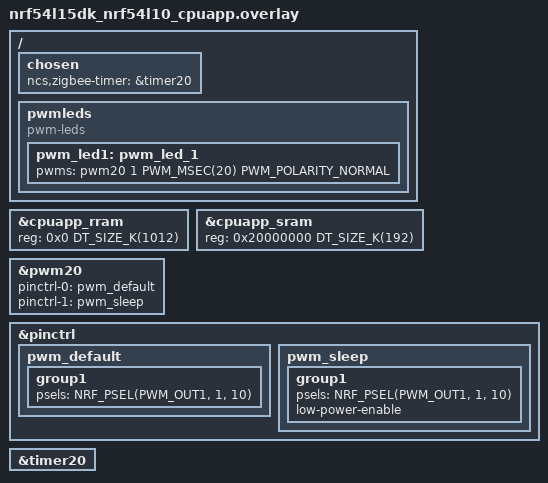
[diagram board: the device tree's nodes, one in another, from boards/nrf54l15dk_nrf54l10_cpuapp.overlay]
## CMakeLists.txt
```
#
# Copyright (c) 2024 Nordic Semiconductor ASA
#
# SPDX-License-Identifier: LicenseRef-Nordic-5-Clause
#

cmake_minimum_required(VERSION 3.20.0)

find_package(Zephyr REQUIRED HINTS $ENV{ZEPHYR_BASE})

project("Zigbee Light Bulb")

target_sources(app PRIVATE
	src/main.cpp
	src/app_task_zigbee.cpp
	src/zboss_mem_globals.c
)

target_include_directories(app PRIVATE include)

# LTO link: zb_memconfig.o from prebuilts is plain ELF (weak gc_*); strong gc_*
# in zb_mem_config_context.h must not be LTO bytecode or ld warns about symbol size.
if(CONFIG_LTO)
	set_source_files_properties(
		src/zboss_mem_globals.c
		PROPERTIES COMPILE_OPTIONS -fno-lto
	)
endif()
```

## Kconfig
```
#
# Copyright (c) 2026 Nordic Semiconductor ASA
#
# SPDX-License-Identifier: LicenseRef-Nordic-5-Clause
#

if ZIGBEE_BT_DFU

config BT_DEVICE_NAME
	default "Zigbee_Bulb"

endif # ZIGBEE_BT_DFU

config MPSL_THREAD_COOP_PRIO
	default 8

source "Kconfig.zephyr"
```

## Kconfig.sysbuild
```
#
# Copyright (c) 2024 Nordic Semiconductor
#
# SPDX-License-Identifier: LicenseRef-Nordic-5-Clause
#

config NRF_DEFAULT_IPC_RADIO
	default y

# Enable IEEE802.15.4 serialization to network core for Zigbee
config NETCORE_IPC_RADIO_IEEE802154
	default y if SOC_SERIES_NRF53

if BOOTLOADER_MCUBOOT

#### DFU multi-image support
config DFU_MULTI_IMAGE_PACKAGE_BUILD
	default y

config DFU_MULTI_IMAGE_PACKAGE_APP
	default y

#### DFU dual core configuration
if SOC_SERIES_NRF53

config PM_EXTERNAL_FLASH_MCUBOOT_SECONDARY
	default y

config MCUBOOT_UPDATEABLE_IMAGES
	default 2

choice MCUBOOT_MODE
	default MCUBOOT_MODE_OVERWRITE_ONLY
endchoice

config SECURE_BOOT_NETCORE
	default y

config NETCORE_APP_UPDATE
	default y

config DFU_MULTI_IMAGE_PACKAGE_NET
	default y

config MCUBOOT_NRF53_MULTI_IMAGE_UPDATE
	default y if NETCORE_APP_UPDATE

endif # SOC_SERIES_NRF53

endif # BOOTLOADER_MCUBOOT

source "${ZEPHYR_BASE}/share/sysbuild/Kconfig"
```

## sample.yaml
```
sample:
  description: Zigbee Light control - light bulb sample
  name: Zigbee Light control
common:
  tags:
    - ci_build
    - smoke
    - sysbuild
    - ci_samples_zigbee
tests:
  sample.zigbee.light_bulb:
    sysbuild: true
    build_only: true
    integration_platforms:
      - nrf52840dk/nrf52840
      - nrf5340dk/nrf5340/cpuapp
      - nrf54l15dk/nrf54l15/cpuapp
      - nrf54lc10dk/nrf54lc10a/cpuapp
      - nrf54lm20dk/nrf54lm20b/cpuapp
      - nrf54lm20dongle/nrf54lm20b/cpuapp
    platform_allow:
      - nrf52840dk/nrf52840
      - nrf5340dk/nrf5340/cpuapp
      - nrf54l15dk/nrf54l10/cpuapp
      - nrf54l15dk/nrf54l15/cpuapp
      - nrf54lc10dk/nrf54lc10a/cpuapp
      - nrf54lm20dk/nrf54lm20a/cpuapp
      - nrf54lm20dk/nrf54lm20b/cpuapp
      - nrf54lm20dongle/nrf54lm20b/cpuapp
  sample.zigbee.light_bulb.fota:
    sysbuild: true
    build_only: true
    extra_args:
      - FILE_SUFFIX=fota
      - SNIPPET=zigbee_fota
    integration_platforms:
      - nrf52840dk/nrf52840
      - nrf5340dk/nrf5340/cpuapp
      - nrf54l15dk/nrf54l15/cpuapp
      - nrf54lm20dk/nrf54lm20b/cpuapp
    platform_allow:
      - nrf52840dk/nrf52840
      - nrf5340dk/nrf5340/cpuapp
      - nrf54l15dk/nrf54l10/cpuapp
      - nrf54l15dk/nrf54l15/cpuapp
      - nrf54lm20dk/nrf54lm20a/cpuapp
      - nrf54lm20dk/nrf54lm20b/cpuapp
  sample.zigbee.light_bulb.fota_and_bt_dfu:
    sysbuild: true
    build_only: true
    extra_args:
      - FILE_SUFFIX=fota
      - SNIPPET=zigbee_fota
      - CONFIG_ZIGBEE_BT_DFU=y
    integration_platforms:
      - nrf54lm20dk/nrf54lm20b/cpuapp
    platform_allow:
      - nrf54lm20dk/nrf54lm20a/cpuapp
      - nrf54lm20dk/nrf54lm20b/cpuapp
  sample.zigbee.light_bulb.io_shell:
    sysbuild: true
    build_only: true
    extra_args: light_bulb_SNIPPET=io_shell
    integration_platforms:
      - nrf54lm20dongle/nrf54lm20b/cpuapp
    platform_allow:
      - nrf54lm20dongle/nrf54lm20b/cpuapp
  sample.zigbee.light_bulb.with_shell:
    sysbuild: true
    build_only: true
    extra_args:
      - CONFIG_ZIGBEE_SHELL=y
      - CONFIG_ZIGBEE_SHELL_DEBUG_CMD=y
      - CONFIG_ZIGBEE_LOGGER_EP=n
      - CONFIG_ZIGBEE_SHELL_ENDPOINT=10
      - CONFIG_LOG_MODE_DEFERRED=y
      - CONFIG_ZIGBEE_TOUCHLINK_TARGET=y
    platform_allow:
      - nrf52840dk/nrf52840
      - nrf5340dk/nrf5340/cpuapp
      - nrf54l15dk/nrf54l10/cpuapp
      - nrf54l15dk/nrf54l15/cpuapp
      - nrf54lc10dk/nrf54lc10a/cpuapp
      - nrf54lm20dk/nrf54lm20a/cpuapp
      - nrf54lm20dk/nrf54lm20b/cpuapp
    tags:
      - no_integration
      - shell
```

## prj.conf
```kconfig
#
# Copyright (c) 2024 Nordic Semiconductor ASA
#
# SPDX-License-Identifier: LicenseRef-Nordic-5-Clause
#

CONFIG_NCS_SAMPLES_DEFAULTS=y

CONFIG_UART_INTERRUPT_DRIVEN=y
CONFIG_SERIAL=y
CONFIG_GPIO=y
CONFIG_PWM=y

# Make sure printk is not printing to the UART console
CONFIG_CONSOLE=y
CONFIG_UART_CONSOLE=y

CONFIG_HEAP_MEM_POOL_SIZE=2048
CONFIG_MAIN_THREAD_PRIORITY=7

CONFIG_ZIGBEE_ADD_ON=y
CONFIG_ZIGBEE_APP_UTILS=y
CONFIG_ZIGBEE_ROLE_ROUTER=y

# Enable DK LED and Buttons library
CONFIG_DK_LIBRARY=y
# Scene extension
CONFIG_ZIGBEE_SCENES=y
```

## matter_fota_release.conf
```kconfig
#
# Copyright (c) 2026 Nordic Semiconductor ASA
#
# SPDX-License-Identifier: LicenseRef-Nordic-5-Clause
#
# Release/size-optimization configuration for combined Zigbee + Matter + Thread (PoC)
# Disables logging, console, and other debug features to reduce flash usage

#######################
# Release Optimizations
#######################

# Disable all debug features
CONFIG_USE_SEGGER_RTT=n
CONFIG_SHELL=n
CONFIG_OPENTHREAD_SHELL=n
CONFIG_CONSOLE=n
CONFIG_UART_CONSOLE=n
CONFIG_SERIAL=n
CONFIG_UART_INTERRUPT_DRIVEN=n
CONFIG_LOG=n
CONFIG_LOG_MODE_MINIMAL=n
CONFIG_ASSERT_VERBOSE=n
CONFIG_ASSERT_NO_FILE_INFO=y
CONFIG_PRINTK=n
CONFIG_PRINTK_SYNC=n
CONFIG_BOOT_BANNER=n

# TODO: Enable LTO to decrease the flash usage after testing
# CONFIG_LTO=y
# CONFIG_ISR_TABLES_LOCAL_DECLARATION=y

# Additional size optimizations
CONFIG_SIZE_OPTIMIZATIONS=y
CONFIG_COMPILER_OPT="-Os"
```

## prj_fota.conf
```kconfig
#
# Copyright (c) 2026 Nordic Semiconductor ASA
#
# SPDX-License-Identifier: LicenseRef-Nordic-5-Clause
#

CONFIG_NCS_SAMPLES_DEFAULTS=y

CONFIG_UART_INTERRUPT_DRIVEN=y
CONFIG_SERIAL=y
CONFIG_GPIO=y
CONFIG_PWM=y

CONFIG_CONSOLE=y
CONFIG_UART_CONSOLE=y

CONFIG_HEAP_MEM_POOL_SIZE=2048
CONFIG_MAIN_THREAD_PRIORITY=7

CONFIG_ZIGBEE_ADD_ON=y
CONFIG_ZIGBEE_APP_UTILS=y
CONFIG_ZIGBEE_ROLE_ROUTER=y

CONFIG_DK_LIBRARY=y
CONFIG_ZIGBEE_SCENES=y

#######################
# Zigbee FOTA overlay #
#######################

CONFIG_ZIGBEE_FOTA=y
CONFIG_ZIGBEE_FOTA_HW_VERSION=52
CONFIG_ZIGBEE_FOTA_ENDPOINT=11
CONFIG_MCUBOOT_IMGTOOL_SIGN_VERSION="1.2.3"
CONFIG_ZIGBEE_FOTA_COMMENT="light_bulb"
CONFIG_ZIGBEE_FOTA_DOWNLOAD_RESUME=y

CONFIG_IMG_MANAGER=y
CONFIG_STREAM_FLASH=y
CONFIG_DFU_TARGET_MCUBOOT=y
CONFIG_IMG_ERASE_PROGRESSIVELY=y
CONFIG_ZIGBEE_FOTA_PROGRESS_EVT=y

CONFIG_NRF_802154_RX_BUFFERS=32
```

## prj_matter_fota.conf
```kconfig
#
# Copyright (c) 2026 Nordic Semiconductor ASA
#
# SPDX-License-Identifier: LicenseRef-Nordic-5-Clause
#
# Debug configuration for combined Zigbee + Matter + Thread (PoC)
# Includes logging, console, and debug features

# Base sample configs
CONFIG_NCS_SAMPLES_DEFAULTS=y

CONFIG_UART_INTERRUPT_DRIVEN=y
CONFIG_SERIAL=y
CONFIG_GPIO=y
CONFIG_PWM=y

# Console
CONFIG_CONSOLE=y
CONFIG_UART_CONSOLE=y

# CONFIG_HEAP_MEM_POOL_SIZE=4096
CONFIG_MAIN_THREAD_PRIORITY=7

#######################
# Zigbee Configuration
#######################

CONFIG_ZIGBEE_ADD_ON=y
CONFIG_ZIGBEE_APP_UTILS=y
# Show Zigbee init/recovery logs (Device first start, network steering recovery).
CONFIG_ZIGBEE_APP_UTILS_LOG_LEVEL_INF=y
CONFIG_ZIGBEE_ROLE_ROUTER=y

# Touchlink target role for the combined Matter build
# CONFIG_ZIGBEE_TOUCHLINK_TARGET=y

# Scene extension
CONFIG_ZIGBEE_SCENES=y

# Enable DK LED and Buttons library
CONFIG_DK_LIBRARY=y

# This example requires more workqueue stack
CONFIG_SYSTEM_WORKQUEUE_STACK_SIZE=2048

CONFIG_ZBOSS_OSIF_LOG_LEVEL_INF=y
CONFIG_ZIGBEE_MATTER_COEXISTENCE_LOG_LEVEL_INF=y

#######################
# Zigbee FOTA Configuration
#######################

# FIXME: Disabled Zigbee FOTA for initial development
# # Enable Zigbee FOTA library
# CONFIG_ZIGBEE_FOTA=y
# CONFIG_ZIGBEE_FOTA_HW_VERSION=52
# CONFIG_ZIGBEE_FOTA_ENDPOINT=5
# CONFIG_MCUBOOT_IMGTOOL_SIGN_VERSION="1.0.0"
# CONFIG_ZIGBEE_FOTA_COMMENT="light_bulb_matter"

# # Ensure an MCUboot-compatible binary is generated.
# CONFIG_IMG_MANAGER=y
# CONFIG_STREAM_FLASH=y
# CONFIG_DFU_TARGET_MCUBOOT=y
# CONFIG_IMG_ERASE_PROGRESSIVELY=y
# CONFIG_ZIGBEE_FOTA_PROGRESS_EVT=y

# # Increase the number of RX buffers for FOTA
# CONFIG_NRF_802154_RX_BUFFERS=32

#######################
# Matter Configuration
#######################

# Enable CHIP (Matter)
CONFIG_CHIP=y
CONFIG_CHIP_PROJECT_CONFIG="include/chip_project_config.h"
CONFIG_CHIP_DEVICE_PRODUCT_NAME="Matter Zigbee Light Bulb"

# Configure ZAP file
CONFIG_NCS_SAMPLE_MATTER_ZAP_FILE_PATH="${APPLICATION_CONFIG_DIR}/src/matter_zap/light_bulb.zap"

# 32773 == 0x8005 (example lighting-app)
CONFIG_CHIP_DEVICE_PRODUCT_ID=32773
CONFIG_STD_CPP17=y

# Enable Matter pairing automatically on application start.
CONFIG_CHIP_ENABLE_PAIRING_AUTOSTART=y

# Enable Matter extended announcement and increase duration to 1 hour.
CONFIG_CHIP_BLE_EXT_ADVERTISING=y
CONFIG_CHIP_BLE_ADVERTISING_DURATION=60

CONFIG_BT_DEVICE_NAME="MatterZigbeeLb"

# Other settings
CONFIG_THREAD_NAME=y
CONFIG_MPU_STACK_GUARD=y
CONFIG_RESET_ON_FATAL_ERROR=n

# Reduce application size
CONFIG_USE_SEGGER_RTT=n

# Increase system workqueue stack for combined protocols (with Thread)
CONFIG_SYSTEM_WORKQUEUE_STACK_SIZE=6144

# Must be a preemptible priority (0–15), not cooperative (-1). With -1, ZBOSS is
# coop priority -1 and is outranked by MPSL Work (prio -8), so it never runs.
# State 128 = _THREAD_QUEUED (runnable); ZBOSS stays queued and never gets CPU.
CONFIG_ZBOSS_DEFAULT_THREAD_PRIORITY=1
CONFIG_ZBOSS_DEFAULT_THREAD_STACK_SIZE=6144

# Libc malloc arena required for Zigbee + Matter coexistence.
# - 0: no libc heap -> Matter init fails (malloc/calloc used during init).
# - -1: "all remaining RAM" -> on this build the computed heap extends past
#   valid RAM and triggers a precise data bus fault in sys_heap_init().
# - Positive value: static BSS heap of that size -> valid heap, no fault.
# Matter uses CHIP_MALLOC_SYS_HEAP for its own allocations; this arena
# covers libc malloc() used elsewhere (init, Zephyr, Zigbee, etc.).
CONFIG_COMMON_LIBC_MALLOC_ARENA_SIZE=-1

## PoC Configuration ##
# Keep Matter shell disabled to avoid getopt conflicts
CONFIG_CHIP_LIB_SHELL=n
CONFIG_NCS_SAMPLE_MATTER_TEST_SHELL=n

# Radio dispatcher 
CONFIG_NRF_802154_CALLBACKS_DISPATCHER=y

# We need it to disable ZBOSS thread
CONFIG_ZIGBEE_DEBUG_FUNCTIONS=y

CONFIG_CHIP_FACTORY_DATA_BUILD=y

# DFU over Bluetooth LE SMP
CONFIG_CHIP_DFU_OVER_BT_SMP=y
```

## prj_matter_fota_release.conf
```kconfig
#
# Copyright (c) 2026 Nordic Semiconductor ASA
#
# SPDX-License-Identifier: LicenseRef-Nordic-5-Clause
#
# Release configuration for combined Zigbee + Matter + Thread (PoC)
# Optimized for minimum memory footprint

# Base sample configs
CONFIG_NCS_SAMPLES_DEFAULTS=y

CONFIG_GPIO=y
CONFIG_PWM=y

CONFIG_HEAP_MEM_POOL_SIZE=4096
CONFIG_MAIN_THREAD_PRIORITY=7

#######################
# Zigbee Configuration
#######################

CONFIG_ZIGBEE_ADD_ON=y
CONFIG_ZIGBEE_APP_UTILS=y
CONFIG_ZIGBEE_ROLE_ROUTER=y

# Scene extension
CONFIG_ZIGBEE_SCENES=y

# Enable DK LED and Buttons library
CONFIG_DK_LIBRARY=y

# This example requires more workqueue stack
CONFIG_SYSTEM_WORKQUEUE_STACK_SIZE=2048

# Networking
CONFIG_NETWORKING=y
CONFIG_NET_IPV6=y
CONFIG_NET_IP_ADDR_CHECK=y
CONFIG_NET_UDP=y
CONFIG_NET_TCP=y
CONFIG_NET_SOCKETS=y

# OpenThread/Thread support for Matter (PoC - not functional with Zigbee)
CONFIG_NET_L2_OPENTHREAD=y
CONFIG_OPENTHREAD_NORDIC_LIBRARY_FTD=y
CONFIG_OPENTHREAD_SLAAC=y
CONFIG_OPENTHREAD_MANUAL_START=y

#######################
# Zigbee FOTA Configuration
#######################

# Enable Zigbee FOTA library
CONFIG_ZIGBEE_FOTA=y
CONFIG_ZIGBEE_FOTA_HW_VERSION=52
CONFIG_ZIGBEE_FOTA_ENDPOINT=5
CONFIG_MCUBOOT_IMGTOOL_SIGN_VERSION="1.0.0"
CONFIG_ZIGBEE_FOTA_COMMENT="light_bulb_matter"

# Ensure an MCUboot-compatible binary is generated.
CONFIG_IMG_MANAGER=y
CONFIG_STREAM_FLASH=y
CONFIG_DFU_TARGET_MCUBOOT=y
CONFIG_IMG_ERASE_PROGRESSIVELY=y
CONFIG_ZIGBEE_FOTA_PROGRESS_EVT=y

# Increase the number of RX buffers for FOTA
CONFIG_NRF_802154_RX_BUFFERS=32

#######################
# Matter Configuration
#######################

# Enable CHIP (Matter)
CONFIG_CHIP=y
CONFIG_CHIP_PROJECT_CONFIG="src/chip_project_config.h"

# Configure ZAP file
CONFIG_NCS_SAMPLE_MATTER_ZAP_FILE_PATH="${APPLICATION_CONFIG_DIR}/src/matter_zap/light_bulb.zap"

# 32773 == 0x8005 (example lighting-app)
CONFIG_CHIP_DEVICE_PRODUCT_ID=32773
CONFIG_STD_CPP17=y

# Enable Matter pairing automatically on application start.
CONFIG_CHIP_ENABLE_PAIRING_AUTOSTART=y

# Enable Matter extended announcement and increase duration to 1 hour.
CONFIG_CHIP_BLE_EXT_ADVERTISING=y
CONFIG_CHIP_BLE_ADVERTISING_DURATION=60

# Bluetooth Low Energy configuration
CONFIG_BT=y
CONFIG_BT_PERIPHERAL=y
CONFIG_BT_DEVICE_NAME="MatterZigbeeLight"
CONFIG_BT_DEVICE_APPEARANCE=0
CONFIG_BT_MAX_CONN=1
CONFIG_BT_L2CAP_TX_MTU=247
CONFIG_BT_BUF_ACL_RX_SIZE=251
CONFIG_BT_BUF_ACL_TX_SIZE=251
CONFIG_BT_RX_STACK_SIZE=1200

# Other settings
CONFIG_THREAD_NAME=n
CONFIG_MPU_STACK_GUARD=y
CONFIG_RESET_ON_FATAL_ERROR=y

# Enable Factory Data feature
CONFIG_CHIP_FACTORY_DATA=y
CONFIG_CHIP_FACTORY_DATA_BUILD=y

# Matter commissioning
CONFIG_CHIP_COMMISSIONABLE_DEVICE_TYPE=y
CONFIG_CHIP_DEVICE_TYPE=256

# Enable Matter OTA (aligned with Zigbee FOTA)
CONFIG_CHIP_OTA_REQUESTOR=y

# Increase system workqueue stack for combined protocols (with Thread)
CONFIG_SYSTEM_WORKQUEUE_STACK_SIZE=4096

# Memory settings for Zigbee + Matter + Thread (PoC)
CONFIG_MAIN_STACK_SIZE=4096
CONFIG_CHIP_MALLOC_SYS_HEAP=y
CONFIG_CHIP_MALLOC_SYS_HEAP_SIZE=32768

# Thread stack sizes
CONFIG_NET_TX_STACK_SIZE=1200
CONFIG_NET_RX_STACK_SIZE=1500

# Crypto - PSA Crypto Backend
CONFIG_NORDIC_SECURITY_BACKEND=y
CONFIG_CHIP_CRYPTO_PSA=y

# Enable legacy mbedTLS crypto for Matter SPAKE2+ (requires mbedtls_ecp_muladd)
CONFIG_MBEDTLS_LEGACY_CRYPTO_C=y
CONFIG_MBEDTLS_ECP_C=y

# Storage - use ZMS for nRF54L (NVS not supported)
CONFIG_ZMS=y
CONFIG_SETTINGS=y
CONFIG_SETTINGS_ZMS=y
CONFIG_FLASH=y
CONFIG_FLASH_MAP=y
CONFIG_MPU_ALLOW_FLASH_WRITE=y

# Trusted storage backend for Matter PSA crypto keys
CONFIG_TRUSTED_STORAGE=y
CONFIG_TRUSTED_STORAGE_BACKEND_AEAD=y
CONFIG_TRUSTED_STORAGE_STORAGE_BACKEND_SETTINGS=y

# Additional platform requirements for Matter
CONFIG_HWINFO=y
CONFIG_REBOOT=y
CONFIG_ENTROPY_GENERATOR=y

# Matter thread requirements
CONFIG_SCHED_CPU_MASK=y

# Watchdog
CONFIG_TASK_WDT=y

# Matter common infrastructure configs (needed even without Thread)

# Enable BT GATT for Matter BLE commissioning
CONFIG_BT_GATT_DYNAMIC_DB=y
CONFIG_BT_GATT_SERVICE_CHANGED=y
CONFIG_BT_GATT_CACHING=y
CONFIG_BT_GATT_ENFORCE_SUBSCRIPTION=n


## PoC Configuration ##
# Note: This configuration links all three stacks (Zigbee, Thread, Matter) for memory estimation
# It will have runtime conflicts as Zigbee and Thread cannot share 802.15.4 radio simultaneously
# This is intentional - goal is to measure maximum memory footprint

# Keep Matter shell disabled to avoid getopt conflicts
CONFIG_CHIP_LIB_SHELL=n
CONFIG_NCS_SAMPLE_MATTER_TEST_SHELL=n

#######################
# Release Optimizations
#######################

# Disable all debug features
CONFIG_USE_SEGGER_RTT=n
CONFIG_SHELL=n
CONFIG_OPENTHREAD_SHELL=n
CONFIG_CONSOLE=n
CONFIG_UART_CONSOLE=n
CONFIG_SERIAL=n
CONFIG_UART_INTERRUPT_DRIVEN=n
CONFIG_LOG=n
CONFIG_LOG_MODE_MINIMAL=n
CONFIG_ASSERT_VERBOSE=n
CONFIG_ASSERT_NO_FILE_INFO=y
CONFIG_PRINTK=n
CONFIG_PRINTK_SYNC=n
CONFIG_BOOT_BANNER=n

# Enable LTO to decrease the flash usage
CONFIG_LTO=y
CONFIG_ISR_TABLES_LOCAL_DECLARATION=y

# Additional size optimizations
CONFIG_SIZE_OPTIMIZATIONS=y
CONFIG_COMPILER_OPT="-Os"
```

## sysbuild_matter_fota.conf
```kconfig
#
# Copyright (c) 2026 Nordic Semiconductor ASA
#
# SPDX-License-Identifier: LicenseRef-Nordic-5-Clause
#

# Enable Matter support in sysbuild
SB_CONFIG_MATTER=y
SB_CONFIG_MATTER_FACTORY_DATA_GENERATE=y

# Disable partition manager
SB_CONFIG_PARTITION_MANAGER=n

# MCUBoot configuration
SB_CONFIG_MCUBOOT_MODE_OVERWRITE_ONLY=y
SB_CONFIG_MCUBOOT_COMPRESSED_IMAGE_SUPPORT=y
```

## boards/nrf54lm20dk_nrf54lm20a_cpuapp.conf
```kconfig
#
# Copyright (c) 2026 Nordic Semiconductor ASA
#
# SPDX-License-Identifier: LicenseRef-Nordic-5-Clause
#


# Fixme, the new ECC handling is broken, and let's disable the new feature for now for testing.
# If cracen is fixed, we can enable this again.
CONFIG_CRACEN_ECC_COUNTERMEASURES=n
```

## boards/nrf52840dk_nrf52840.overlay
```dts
/*
 * Copyright (c) 2025 Nordic Semiconductor ASA
 *
 * SPDX-License-Identifier: LicenseRef-Nordic-5-Clause
 */

#include <nrf52840_partitions.dtsi>

/ {
	pwmleds {
		pwm_led1: pwm_led_1 {
			pwms = <&pwm0 1 PWM_MSEC(20) PWM_POLARITY_INVERTED>;
		};
	};

	chosen {
		ncs,zigbee-timer = &timer2;
	};
};

&pwm0 {
	pinctrl-0 = <&pwm0_default_alt>;
	pinctrl-1 = <&pwm0_sleep_alt>;
	pinctrl-names = "default", "sleep";
};

&pinctrl {
	pwm0_default_alt: pwm0_default_alt {
		group1 {
			psels = <NRF_PSEL(PWM_OUT1, 0, 14)>;
			nordic,invert;
		};
	};

	pwm0_sleep_alt: pwm0_sleep_alt {
		group1 {
			psels = <NRF_PSEL(PWM_OUT1, 0, 14)>;
			low-power-enable;
		};
	};
};

&timer2 {
	status = "okay";
};
```

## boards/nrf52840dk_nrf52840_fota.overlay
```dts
/*
 * Copyright (c) 2026 Nordic Semiconductor ASA
 *
 * SPDX-License-Identifier: LicenseRef-Nordic-5-Clause
 */

#include <nrf52840_partitions.dtsi>
#include <ext_flash/nrf52840dk_partitions.dtsi>

/ {
	pwmleds {
		pwm_led1: pwm_led_1 {
			pwms = <&pwm0 1 PWM_MSEC(20) PWM_POLARITY_INVERTED>;
		};
	};

	chosen {
		ncs,zigbee-timer = &timer2;
	};
};

&pwm0 {
	pinctrl-0 = <&pwm0_default_alt>;
	pinctrl-1 = <&pwm0_sleep_alt>;
	pinctrl-names = "default", "sleep";
};

&pinctrl {
	pwm0_default_alt: pwm0_default_alt {
		group1 {
			psels = <NRF_PSEL(PWM_OUT1, 0, 14)>;
			nordic,invert;
		};
	};

	pwm0_sleep_alt: pwm0_sleep_alt {
		group1 {
			psels = <NRF_PSEL(PWM_OUT1, 0, 14)>;
			low-power-enable;
		};
	};
};

&timer2 {
	status = "okay";
};
```

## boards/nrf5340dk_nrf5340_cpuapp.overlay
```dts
/*
 * Copyright (c) 2025 Nordic Semiconductor ASA
 *
 * SPDX-License-Identifier: LicenseRef-Nordic-5-Clause
 */

#include <nrf5340_cpuapp_partitions.dtsi>

/ {
	pwmleds {
		compatible = "pwm-leds";

		pwm_led1: pwm_led_1 {
			pwms = <&pwm0 1 PWM_MSEC(20) PWM_POLARITY_INVERTED>;
		};
	};

	chosen {
		ncs,zigbee-timer = &timer2;
	};
};

&pwm0 {
	pinctrl-0 = <&pwm0_default_alt>;
	pinctrl-1 = <&pwm0_sleep_alt>;
	pinctrl-names = "default", "sleep";
};

&pinctrl {
	pwm0_default_alt: pwm0_default_alt {
		group1 {
			psels = <NRF_PSEL(PWM_OUT1, 0, 29)>;
			nordic,invert;
		};
	};

	pwm0_sleep_alt: pwm0_sleep_alt {
		group1 {
			psels = <NRF_PSEL(PWM_OUT1, 0, 29)>;
			low-power-enable;
		};
	};
};

&timer2 {
	status = "okay";
};
```

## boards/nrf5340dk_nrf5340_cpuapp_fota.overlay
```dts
/*
 * Copyright (c) 2026 Nordic Semiconductor ASA
 *
 * SPDX-License-Identifier: LicenseRef-Nordic-5-Clause
 */

#include <nrf5340_cpuapp_partitions.dtsi>
#include <ext_flash/nrf5340dk_cpuapp_partitions.dtsi>

/ {
	pwmleds {
		compatible = "pwm-leds";

		pwm_led1: pwm_led_1 {
			pwms = <&pwm0 1 PWM_MSEC(20) PWM_POLARITY_INVERTED>;
		};
	};

	chosen {
		ncs,zigbee-timer = &timer2;
	};
};

&pwm0 {
	status = "okay";
	pinctrl-0 = <&pwm0_default_alt>;
	pinctrl-1 = <&pwm0_sleep_alt>;
	pinctrl-names = "default", "sleep";
};

&pinctrl {
	pwm0_default_alt: pwm0_default_alt {
		group1 {
			psels = <NRF_PSEL(PWM_OUT1, 0, 29)>;
			nordic,invert;
		};
	};

	pwm0_sleep_alt: pwm0_sleep_alt {
		group1 {
			psels = <NRF_PSEL(PWM_OUT1, 0, 29)>;
			low-power-enable;
		};
	};
};

&timer2 {
	status = "okay";
};
```

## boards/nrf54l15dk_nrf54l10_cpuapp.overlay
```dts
/*
 * Copyright (c) 2024 Nordic Semiconductor ASA
 *
 * SPDX-License-Identifier: LicenseRef-Nordic-5-Clause
 */

#include <nrf54l10_cpuapp_partitions.dtsi>

/ {
	chosen {
		ncs,zigbee-timer = &timer20;
	};

	pwmleds {
		compatible = "pwm-leds";

		pwm_led1: pwm_led_1 {
			pwms = <&pwm20 1 PWM_MSEC(20) PWM_POLARITY_NORMAL>;
		};
	};
};

// restore full RRAM and SRAM space - by default some parts are dedicated to FLPR
&cpuapp_rram {
	reg = <0x0 DT_SIZE_K(1012)>;
};

&cpuapp_sram {
	reg = <0x20000000 DT_SIZE_K(192)>;
	ranges = <0x0 0x20000000 DT_SIZE_K(192)>;
};

&pwm20 {
	status = "okay";
	pinctrl-0 = <&pwm_default>;
	pinctrl-1 = <&pwm_sleep>;
	pinctrl-names = "default", "sleep";
};

&pinctrl {
	pwm_default: pwm_default {
		group1 {
			psels = <NRF_PSEL(PWM_OUT1, 1, 10)>;
		};
	};

	pwm_sleep: pwm_sleep {
		group1 {
			psels = <NRF_PSEL(PWM_OUT1, 1, 10)>;
			low-power-enable;
		};
	};
};

&timer20 {
	status = "okay";
};
```

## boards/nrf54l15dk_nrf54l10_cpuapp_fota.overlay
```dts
/*
 * Copyright (c) 2026 Nordic Semiconductor ASA
 *
 * SPDX-License-Identifier: LicenseRef-Nordic-5-Clause
 */

#include <nrf54l10_cpuapp_partitions.dtsi>
#include <ext_flash/nrf54l10dk_cpuapp_partitions.dtsi>
```

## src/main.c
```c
/*
 * Copyright (c) 2024 Nordic Semiconductor ASA
 *
 * SPDX-License-Identifier: LicenseRef-Nordic-5-Clause
 */

/** @file
 *
 * @brief Simple Zigbee light bulb implementation.
 */

#include <zephyr/types.h>
#include <zephyr/kernel.h>
#include <zephyr/device.h>
#include <soc.h>
#include <zephyr/drivers/pwm.h>
#include <zephyr/logging/log.h>
#include <dk_buttons_and_leds.h>
#include <zephyr/settings/settings.h>

#include <zboss_api.h>
#include <zboss_api_addons.h>
#include <zb_mem_config_med.h>
#include <zigbee/zigbee_app_utils.h>
#include <zigbee/zigbee_error_handler.h>
#include <zigbee/zigbee_zcl_scenes.h>
#include <zboss_api_zcl.h>
#include <zboss_api_zdo.h>
#include <zb_nrf_platform.h>
#include "zb_dimmable_light.h"

#define RUN_STATUS_LED                  DK_LED1
#define RUN_LED_BLINK_INTERVAL          1000

/* Device endpoint, used to receive light controlling commands. */
#define DIMMABLE_LIGHT_ENDPOINT         10

/* Version of the application software (1 byte). */
#define BULB_INIT_BASIC_APP_VERSION     01

/* Version of the implementation of the Zigbee stack (1 byte). */
#define BULB_INIT_BASIC_STACK_VERSION   10

/* Version of the hardware of the device (1 byte). */
#define BULB_INIT_BASIC_HW_VERSION      11

/* Manufacturer name (32 bytes). */
#define BULB_INIT_BASIC_MANUF_NAME      "Nordic"

/* Model number assigned by manufacturer (32-bytes long string). */
#define BULB_INIT_BASIC_MODEL_ID        "Dimable_Light_v0.1"

/* First 8 bytes specify the date of manufacturer of the device
 * in ISO 8601 format (YYYYMMDD). The rest (8 bytes) are manufacturer specific.
 */
#define BULB_INIT_BASIC_DATE_CODE       "20200329"

/* Type of power sources available for the device.
 * For possible values see section 3.2.2.2.8 of ZCL specification.
 */
#define BULB_INIT_BASIC_POWER_SOURCE    ZB_ZCL_BASIC_POWER_SOURCE_DC_SOURCE

/* Describes the physical location of the device (16 bytes).
 * May be modified during commissioning process.
 */
#define BULB_INIT_BASIC_LOCATION_DESC   "Office desk"

/* Describes the type of physical environment.
 * For possible values see section 3.2.2.2.10 of ZCL specification.
 */
#define BULB_INIT_BASIC_PH_ENV          ZB_ZCL_BASIC_ENV_UNSPECIFIED

/* LED indicating that light switch successfully joind Zigbee network. */
#define ZIGBEE_NETWORK_STATE_LED        DK_LED3

/* LED immitaing dimmable light bulb - define for informational
 * purposes only.
 */
#define BULB_LED                        DK_LED4

/* Button used to enter the Bulb into the Identify mode. */
#define IDENTIFY_MODE_BUTTON            DK_BTN4_MSK

/* Use onboard led4 to act as a light bulb.
 * The app.overlay file has this at node label "pwm_led3" in /pwmleds.
 */
#define PWM_DK_LED_NODE                DT_NODELABEL(pwm_led3)

#if DT_NODE_HAS_STATUS(PWM_DK_LED_NODE, okay)
static const struct pwm_dt_spec led_pwm = PWM_DT_SPEC_GET(PWM_DK_LED_NODE);
#else
#error "Choose supported PWM driver"
#endif

/* Led PWM period, calculated for 100 Hz signal - in microseconds. */
#define LED_PWM_PERIOD_US               (USEC_PER_SEC / 100U)

#ifndef ZB_ROUTER_ROLE
#error Define ZB_ROUTER_ROLE to compile router source code.
#endif

/* Button to start Factory Reset */
#define FACTORY_RESET_BUTTON IDENTIFY_MODE_BUTTON

LOG_MODULE_REGISTER(app, LOG_LEVEL_INF);

/* Main application customizable context.
 * Stores all settings and static values.
 */
typedef struct {
	zb_zcl_basic_attrs_ext_t basic_attr;
	zb_zcl_identify_attrs_t identify_attr;
	zb_zcl_scenes_attrs_t scenes_attr;
	zb_zcl_groups_attrs_t groups_attr;
	zb_zcl_on_off_attrs_t on_off_attr;
	zb_zcl_level_control_attrs_t level_control_attr;
} bulb_device_ctx_t;

/* Zigbee device application context storage. */
static bulb_device_ctx_t dev_ctx;

ZB_ZCL_DECLARE_IDENTIFY_ATTRIB_LIST(
	identify_attr_list,
	&dev_ctx.identify_attr.identify_time);

ZB_ZCL_DECLARE_GROUPS_ATTRIB_LIST(
	groups_attr_list,
	&dev_ctx.groups_attr.name_support);

ZB_ZCL_DECLARE_SCENES_ATTRIB_LIST(
	scenes_attr_list,
	&dev_ctx.scenes_attr.scene_count,
	&dev_ctx.scenes_attr.current_scene,
	&dev_ctx.scenes_attr.current_group,
	&dev_ctx.scenes_attr.scene_valid,
	&dev_ctx.scenes_attr.name_support);

ZB_ZCL_DECLARE_BASIC_ATTRIB_LIST_EXT(
	basic_attr_list,
	&dev_ctx.basic_attr.zcl_version,
	&dev_ctx.basic_attr.app_version,
	&dev_ctx.basic_attr.stack_version,
	&dev_ctx.basic_attr.hw_version,
	dev_ctx.basic_attr.mf_name,
	dev_ctx.basic_attr.model_id,
	dev_ctx.basic_attr.date_code,
	&dev_ctx.basic_attr.power_source,
	dev_ctx.basic_attr.location_id,
	&dev_ctx.basic_attr.ph_env,
	dev_ctx.basic_attr.sw_ver);

/* On/Off cluster attributes additions data */
ZB_ZCL_DECLARE_ON_OFF_ATTRIB_LIST(
	on_off_attr_list,
	&dev_ctx.on_off_attr.on_off);

ZB_ZCL_DECLARE_LEVEL_CONTROL_ATTRIB_LIST(
	level_control_attr_list,
	&dev_ctx.level_control_attr.current_level,
	&dev_ctx.level_control_attr.remaining_time);

ZB_DECLARE_DIMMABLE_LIGHT_CLUSTER_LIST(
	dimmable_light_clusters,
	basic_attr_list,
	identify_attr_list,
	groups_attr_list,
	scenes_attr_list,
	on_off_attr_list,
	level_control_attr_list);


ZB_DECLARE_DIMMABLE_LIGHT_EP(
	dimmable_light_ep,
	DIMMABLE_LIGHT_ENDPOINT,
	dimmable_light_clusters);

ZBOSS_DECLARE_DEVICE_CTX_1_EP(
	dimmable_light_ctx,
	dimmable_light_ep);

/**@brief Starts identifying the device.
 *
 * @param  bufid  Unused parameter, required by ZBOSS scheduler API.
 */
static void start_identifying(zb_bufid_t bufid)
{
	ZVUNUSED(bufid);

	if (ZB_JOINED()) {
		/* Check if endpoint is in identifying mode,
		 * if not, put desired endpoint in identifying mode.
		 */
		if (dev_ctx.identify_attr.identify_time ==
		    ZB_ZCL_IDENTIFY_IDENTIFY_TIME_DEFAULT_VALUE) {

			zb_ret_t zb_err_code = zb_bdb_finding_binding_target(
				DIMMABLE_LIGHT_ENDPOINT);

			if (zb_err_code == RET_OK) {
				LOG_INF("Enter identify mode");
			} else if (zb_err_code == RET_INVALID_STATE) {
				LOG_WRN("RET_INVALID_STATE - Cannot enter identify mode");
			} else {
				ZB_ERROR_CHECK(zb_err_code);
			}
		} else {
			LOG_INF("Cancel identify mode");
			zb_bdb_finding_binding_target_cancel();
		}
	} else {
		LOG_WRN("Device not in a network - cannot enter identify mode");
	}
}

/**@brief Callback for button events.
 *
 * @param[in]   button_state  Bitmask containing the state of the buttons.
 * @param[in]   has_changed   Bitmask containing buttons that have changed their state.
 */
static void button_changed(uint32_t button_state, uint32_t has_changed)
{
	if (IDENTIFY_MODE_BUTTON & has_changed) {
		if (IDENTIFY_MODE_BUTTON & button_state) {
			/* Button changed its state to pressed */
		} else {
			/* Button changed its state to released */
			if (was_factory_reset_done()) {
				/* The long press was for Factory Reset */
				LOG_DBG("After Factory Reset - ignore button release");
			} else   {
				/* Button released before Factory Reset */

				/* Start identification mode */
				ZB_SCHEDULE_APP_CALLBACK(start_identifying, 0);
			}
		}
	}

	check_factory_reset_button(button_state, has_changed);
}

/**@brief Function for initializing additional PWM leds. */
static void pwm_led_init(void)
{
	if (!device_is_ready(led_pwm.dev)) {
		LOG_ERR("Error: PWM device %s is not ready",
			led_pwm.dev->name);
	}
}

/**@brief Function for initializing LEDs and Buttons. */
static void configure_gpio(void)
{
	int err;

	err = dk_buttons_init(button_changed);
	if (err) {
		LOG_ERR("Cannot init buttons (err: %d)", err);
	}

	err = dk_leds_init();
	if (err) {
		LOG_ERR("Cannot init LEDs (err: %d)", err);
	}

	pwm_led_init();
}

/**@brief Sets brightness of bulb luminous executive element
 *
 * @param[in] brightness_level Brightness level, allowed values 0 ... 255,
 *                             0 - turn off, 255 - full brightness.
 */
static void light_bulb_set_brightness(zb_uint8_t brightness_level)
{
	uint32_t pulse = brightness_level * LED_PWM_PERIOD_US / 255U;

	if (pwm_set_dt(&led_pwm, PWM_USEC(LED_PWM_PERIOD_US), PWM_USEC(pulse))) {
		LOG_ERR("Pwm led 4 set fails:\n");
		return;
	}
}

/**@brief Function for setting the light bulb brightness.
 *
 * @param[in] new_level   Light bulb brightness value.
 */
static void level_control_set_value(zb_uint16_t new_level)
{
	LOG_INF("Set level value: %i", new_level);

	ZB_ZCL_SET_ATTRIBUTE(
		DIMMABLE_LIGHT_ENDPOINT,
		ZB_ZCL_CLUSTER_ID_LEVEL_CONTROL,
		ZB_ZCL_CLUSTER_SERVER_ROLE,
		ZB_ZCL_ATTR_LEVEL_CONTROL_CURRENT_LEVEL_ID,
		(zb_uint8_t *)&new_level,
		ZB_FALSE);

	light_bulb_set_brightness(new_level);
}

/**@brief Function for turning ON/OFF the light bulb.
 *
 * @param[in]   on   Boolean light bulb state.
 */
static void on_off_set_value(zb_bool_t on)
{
	LOG_INF("Set ON/OFF value: %i", on);

	ZB_ZCL_SET_ATTRIBUTE(
		DIMMABLE_LIGHT_ENDPOINT,
		ZB_ZCL_CLUSTER_ID_ON_OFF,
		ZB_ZCL_CLUSTER_SERVER_ROLE,
		ZB_ZCL_ATTR_ON_OFF_ON_OFF_ID,
		(zb_uint8_t *)&on,
		ZB_FALSE);

	if (on) {
		light_bulb_set_brightness(dev_ctx.level_control_attr.current_level);
	} else {
		light_bulb_set_brightness(0U);
	}
}

/**@brief Function to toggle the identify LED - BULB_LED is used for this.
 *
 * @param  bufid  Unused parameter, required by ZBOSS scheduler API.
 */
static void toggle_identify_led(zb_bufid_t bufid)
{
	static int blink_status;

	light_bulb_set_brightness(((++blink_status) % 2) ? (255U) : (0U));
	ZB_SCHEDULE_APP_ALARM(toggle_identify_led, bufid, ZB_MILLISECONDS_TO_BEACON_INTERVAL(100));
}

/**@brief Function to handle identify notification events on the first endpoint.
 *
 * @param  bufid  Unused parameter, required by ZBOSS scheduler API.
 */
static void identify_cb(zb_bufid_t bufid)
{
	zb_ret_t zb_err_code;

	if (bufid) {
		/* Schedule a self-scheduling function that will toggle the LED. */
		ZB_SCHEDULE_APP_CALLBACK(toggle_identify_led, bufid);
	} else {
		/* Cancel the toggling function alarm and restore current Zigbee LED state. */
		zb_err_code = ZB_SCHEDULE_APP_ALARM_CANCEL(toggle_identify_led, ZB_ALARM_ANY_PARAM);
		ZVUNUSED(zb_err_code);

		if (dev_ctx.on_off_attr.on_off) {
			light_bulb_set_brightness(dev_ctx.level_control_attr.current_level);
		} else {
			light_bulb_set_brightness(0U);
		}
	}
}

/**@brief Function for initializing all clusters attributes.
 */
static void bulb_clusters_attr_init(void)
{
	/* Basic cluster attributes data */
	dev_ctx.basic_attr.zcl_version = ZB_ZCL_VERSION;
	dev_ctx.basic_attr.app_version = BULB_INIT_BASIC_APP_VERSION;
	dev_ctx.basic_attr.stack_version = BULB_INIT_BASIC_STACK_VERSION;
	dev_ctx.basic_attr.hw_version = BULB_INIT_BASIC_HW_VERSION;

	/* Use ZB_ZCL_SET_STRING_VAL to set strings, because the first byte
	 * should contain string length without trailing zero.
	 *
	 * For example "test" string will be encoded as:
	 *   [(0x4), 't', 'e', 's', 't']
	 */
	ZB_ZCL_SET_STRING_VAL(
		dev_ctx.basic_attr.mf_name,
		BULB_INIT_BASIC_MANUF_NAME,
		ZB_ZCL_STRING_CONST_SIZE(BULB_INIT_BASIC_MANUF_NAME));

	ZB_ZCL_SET_STRING_VAL(
		dev_ctx.basic_attr.model_id,
		BULB_INIT_BASIC_MODEL_ID,
		ZB_ZCL_STRING_CONST_SIZE(BULB_INIT_BASIC_MODEL_ID));

	ZB_ZCL_SET_STRING_VAL(
		dev_ctx.basic_attr.date_code,
		BULB_INIT_BASIC_DATE_CODE,
		ZB_ZCL_STRING_CONST_SIZE(BULB_INIT_BASIC_DATE_CODE));

	dev_ctx.basic_attr.power_source = BULB_INIT_BASIC_POWER_SOURCE;

	ZB_ZCL_SET_STRING_VAL(
		dev_ctx.basic_attr.location_id,
		BULB_INIT_BASIC_LOCATION_DESC,
		ZB_ZCL_STRING_CONST_SIZE(BULB_INIT_BASIC_LOCATION_DESC));

	dev_ctx.basic_attr.ph_env = BULB_INIT_BASIC_PH_ENV;

	/* Identify cluster attributes data. */
	dev_ctx.identify_attr.identify_time =
		ZB_ZCL_IDENTIFY_IDENTIFY_TIME_DEFAULT_VALUE;

	/* On/Off cluster attributes data. */
	dev_ctx.on_off_attr.on_off = (zb_bool_t)ZB_ZCL_ON_OFF_IS_ON;

	dev_ctx.level_control_attr.current_level =
		ZB_ZCL_LEVEL_CONTROL_LEVEL_MAX_VALUE;
	dev_ctx.level_control_attr.remaining_time =
		ZB_ZCL_LEVEL_CONTROL_REMAINING_TIME_DEFAULT_VALUE;

	ZB_ZCL_SET_ATTRIBUTE(
		DIMMABLE_LIGHT_ENDPOINT,
		ZB_ZCL_CLUSTER_ID_ON_OFF,
		ZB_ZCL_CLUSTER_SERVER_ROLE,
		ZB_ZCL_ATTR_ON_OFF_ON_OFF_ID,
		(zb_uint8_t *)&dev_ctx.on_off_attr.on_off,
		ZB_FALSE);

	ZB_ZCL_SET_ATTRIBUTE(
		DIMMABLE_LIGHT_ENDPOINT,
		ZB_ZCL_CLUSTER_ID_LEVEL_CONTROL,
		ZB_ZCL_CLUSTER_SERVER_ROLE,
		ZB_ZCL_ATTR_LEVEL_CONTROL_CURRENT_LEVEL_ID,
		(zb_uint8_t *)&dev_ctx.level_control_attr.current_level,
		ZB_FALSE);
}

/**@brief Callback function for handling ZCL commands.
 *
 * @param[in]   bufid   Reference to Zigbee stack buffer
 *                      used to pass received data.
 */
static void zcl_device_cb(zb_bufid_t bufid)
{
	zb_uint8_t cluster_id;
	zb_uint8_t attr_id;
	zb_zcl_device_callback_param_t  *device_cb_param =
		ZB_BUF_GET_PARAM(bufid, zb_zcl_device_callback_param_t);

	LOG_INF("%s id %hd", __func__, device_cb_param->device_cb_id);

	/* Set default response value. */
	device_cb_param->status = RET_OK;

	switch (device_cb_param->device_cb_id) {
	case ZB_ZCL_LEVEL_CONTROL_SET_VALUE_CB_ID:
		LOG_INF("Level control setting to %d",
			device_cb_param->cb_param.level_control_set_value_param
			.new_value);
		level_control_set_value(
			device_cb_param->cb_param.level_control_set_value_param
			.new_value);
		break;

	case ZB_ZCL_SET_ATTR_VALUE_CB_ID:
		cluster_id = device_cb_param->cb_param.
			     set_attr_value_param.cluster_id;
		attr_id = device_cb_param->cb_param.
			  set_attr_value_param.attr_id;

		if (cluster_id == ZB_ZCL_CLUSTER_ID_ON_OFF) {
			uint8_t value =
				device_cb_param->cb_param.set_attr_value_param
				.values.data8;

			LOG_INF("on/off attribute setting to %hd", value);
			if (attr_id == ZB_ZCL_ATTR_ON_OFF_ON_OFF_ID) {
				on_off_set_value((zb_bool_t)value);
			}
		} else if (cluster_id == ZB_ZCL_CLUSTER_ID_LEVEL_CONTROL) {
			uint16_t value = device_cb_param->cb_param.
					 set_attr_value_param.values.data16;

			LOG_INF("level control attribute setting to %hd",
				value);
			if (attr_id ==
			    ZB_ZCL_ATTR_LEVEL_CONTROL_CURRENT_LEVEL_ID) {
				level_control_set_value(value);
			}
		} else {
			/* Other clusters can be processed here */
			LOG_INF("Unhandled cluster attribute id: %d",
				cluster_id);
			device_cb_param->status = RET_NOT_IMPLEMENTED;
		}
		break;

	default:
		if (zcl_scenes_cb(bufid) == ZB_FALSE) {
			device_cb_param->status = RET_NOT_IMPLEMENTED;
		}
		break;
	}

	LOG_INF("%s status: %hd", __func__, device_cb_param->status);
}

/**@brief Zigbee stack event handler.
 *
 * @param[in]   bufid   Reference to the Zigbee stack buffer
 *                      used to pass signal.
 */
void zboss_signal_handler(zb_bufid_t bufid)
{
	/* Update network status LED. */
	zigbee_led_status_update(bufid, ZIGBEE_NETWORK_STATE_LED);

#if defined(CONFIG_ZIGBEE_TOUCHLINK_TARGET)
	zigbee_touchlink_target_signal_handler(bufid);
#endif

	ZB_ERROR_CHECK(zigbee_default_signal_handler(bufid));

	/* All callbacks should either reuse or free passed buffers.
	 * If bufid == 0, the buffer is invalid (not passed).
	 */
	if (bufid) {
		zb_buf_free(bufid);
	}
}

int main(void)
{
	int blink_status = 0;
	int err;

	LOG_INF("Starting Zigbee R23 Light Bulb example");

	/* Initialize */
	configure_gpio();
	err = settings_subsys_init();
	if (err) {
		LOG_ERR("settings initialization failed");
	}
	register_factory_reset_button(FACTORY_RESET_BUTTON);

	/* Register callback for handling ZCL commands. */
	ZB_ZCL_REGISTER_DEVICE_CB(zcl_device_cb);

	/* Register dimmer switch device context (endpoints). */
	ZB_AF_REGISTER_DEVICE_CTX(&dimmable_light_ctx);

	bulb_clusters_attr_init();
	level_control_set_value(dev_ctx.level_control_attr.current_level);

	/* Register handler to identify notifications. */
	ZB_AF_SET_IDENTIFY_NOTIFICATION_HANDLER(DIMMABLE_LIGHT_ENDPOINT, identify_cb);

	/* Initialize ZCL scene table */
	zcl_scenes_init();

	/* Settings should be loaded after zcl_scenes_init */
	err = settings_load();
	if (err) {
		LOG_ERR("settings loading failed");
	}

	/* Start Zigbee default thread */
	zigbee_enable();

	LOG_INF("Zigbee R23 Light Bulb example started");

	while (1) {
		dk_set_led(RUN_STATUS_LED, (++blink_status) % 2);
		k_sleep(K_MSEC(RUN_LED_BLINK_INTERVAL));
	}
}
```

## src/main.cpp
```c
/*
 * Copyright (c) 2024-2026 Nordic Semiconductor ASA
 *
 * SPDX-License-Identifier: LicenseRef-Nordic-5-Clause
 */

/** @file
 *
 * @brief Zigbee light bulb entry point.
 */

#include "app_task_zigbee.h"

int main(void)
{
	return ZigbeeStart();
}
```

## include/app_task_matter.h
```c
/*
 * Copyright (c) 2026 Nordic Semiconductor ASA
 *
 * SPDX-License-Identifier: LicenseRef-Nordic-5-Clause
 */

#pragma once

#include "board/board.h"
#include "pwm/pwm_device.h"

#include <platform/CHIPDeviceLayer.h>

struct k_timer;
struct Identify;

enum class LightingActor : uint8_t { Remote, Button };

struct LightingEvent {
  uint8_t Action;
  LightingActor Actor;
};

class AppTask {
public:
  static AppTask &Instance() {
    static AppTask sAppTask;
    return sAppTask;
  };

  CHIP_ERROR StartApp();

  void UpdateClusterState();
  void InitPWMDDevice();
  Nrf::PWMDevice &GetPWMDevice() { return mPWMDevice; }

private:
  CHIP_ERROR Init();

  static void LightingActionEventHandler(const LightingEvent &event);
  static void ButtonEventHandler(Nrf::ButtonState state,
                                 Nrf::ButtonMask hasChanged);

  static void ActionInitiated(Nrf::PWMDevice::Action_t action, int32_t actor);
  static void ActionCompleted(Nrf::PWMDevice::Action_t action, int32_t actor);

  Nrf::PWMDevice mPWMDevice;
};
```

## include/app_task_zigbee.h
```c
/*
 * Copyright (c) 2026 Nordic Semiconductor ASA
 *
 * SPDX-License-Identifier: LicenseRef-Nordic-5-Clause
 */

#ifndef APP_TASK_ZIGBEE_H
#define APP_TASK_ZIGBEE_H 1

#ifdef __cplusplus
extern "C" {
#endif

int ZigbeeStart(void);

#ifdef __cplusplus
}
#endif

#endif /* APP_TASK_ZIGBEE_H */
```

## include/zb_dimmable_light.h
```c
/*
 * Copyright (c) 2024 Nordic Semiconductor ASA
 *
 * SPDX-License-Identifier: LicenseRef-Nordic-5-Clause
 */

#ifndef ZB_DIMMABLE_LIGHT_H
#define ZB_DIMMABLE_LIGHT_H 1

/**
 *  @defgroup ZB_DEFINE_DEVICE_DIMMABLE_LIGHT Dimmable Light
 *  @{
 *  @details
 *      - @ref ZB_ZCL_BASIC \n
 *      - @ref ZB_ZCL_IDENTIFY \n
 *      - @ref ZB_ZCL_SCENES \n
 *      - @ref ZB_ZCL_GROUPS \n
 *      - @ref ZB_ZCL_ON_OFF \n
 *      - @ref ZB_ZCL_LEVEL_CONTROL
 */

/** Dimmable Light Device ID */
#define ZB_DIMMABLE_LIGHT_DEVICE_ID 0x0101

/** Dimmable light device version */
#define ZB_DEVICE_VER_DIMMABLE_LIGHT 1

/** @cond internals_doc */

/** Dimmable Light IN (server) clusters number */
#define ZB_DIMMABLE_LIGHT_IN_CLUSTER_NUM 6

/** Dimmable Light OUT (client) clusters number */
#define ZB_DIMMABLE_LIGHT_OUT_CLUSTER_NUM 0

/** Dimmable light total (IN+OUT) cluster number */
#define ZB_DIMMABLE_LIGHT_CLUSTER_NUM \
	(ZB_DIMMABLE_LIGHT_IN_CLUSTER_NUM + ZB_DIMMABLE_LIGHT_OUT_CLUSTER_NUM)

/** Number of attribute for reporting on Dimmable Light device */
#define ZB_DIMMABLE_LIGHT_REPORT_ATTR_COUNT \
	(ZB_ZCL_ON_OFF_REPORT_ATTR_COUNT + ZB_ZCL_LEVEL_CONTROL_REPORT_ATTR_COUNT)

/** Continuous value change attribute count */
#define ZB_DIMMABLE_LIGHT_CVC_ATTR_COUNT 1

/** @endcond */ /* internals_doc */

/**
 * @brief Declare cluster list for Dimmable Light device
 * @param cluster_list_name - cluster list variable name
 * @param basic_attr_list - attribute list for Basic cluster
 * @param identify_attr_list - attribute list for Identify cluster
 * @param groups_attr_list - attribute list for Groups cluster
 * @param scenes_attr_list - attribute list for Scenes cluster
 * @param on_off_attr_list - attribute list for On/Off cluster
 * @param level_control_attr_list - attribute list for Level Control cluster
 */
#define ZB_DECLARE_DIMMABLE_LIGHT_CLUSTER_LIST(					   \
	cluster_list_name,							   \
	basic_attr_list,							   \
	identify_attr_list,							   \
	groups_attr_list,							   \
	scenes_attr_list,							   \
	on_off_attr_list,							   \
	level_control_attr_list)						   \
	zb_zcl_cluster_desc_t cluster_list_name[] =				   \
	{									   \
		ZB_ZCL_CLUSTER_DESC(						   \
			ZB_ZCL_CLUSTER_ID_IDENTIFY,				   \
			ZB_ZCL_ARRAY_SIZE(identify_attr_list, zb_zcl_attr_t),	   \
			(identify_attr_list),					   \
			ZB_ZCL_CLUSTER_SERVER_ROLE,				   \
			ZB_ZCL_MANUF_CODE_INVALID				   \
		),								   \
		ZB_ZCL_CLUSTER_DESC(						   \
			ZB_ZCL_CLUSTER_ID_BASIC,				   \
			ZB_ZCL_ARRAY_SIZE(basic_attr_list, zb_zcl_attr_t),	   \
			(basic_attr_list),					   \
			ZB_ZCL_CLUSTER_SERVER_ROLE,				   \
			ZB_ZCL_MANUF_CODE_INVALID				   \
		),								   \
		ZB_ZCL_CLUSTER_DESC(						   \
			ZB_ZCL_CLUSTER_ID_SCENES,				   \
			ZB_ZCL_ARRAY_SIZE(scenes_attr_list, zb_zcl_attr_t),	   \
			(scenes_attr_list),					   \
			ZB_ZCL_CLUSTER_SERVER_ROLE,				   \
			ZB_ZCL_MANUF_CODE_INVALID				   \
		),								   \
		ZB_ZCL_CLUSTER_DESC(						   \
			ZB_ZCL_CLUSTER_ID_GROUPS,				   \
			ZB_ZCL_ARRAY_SIZE(groups_attr_list, zb_zcl_attr_t),	   \
			(groups_attr_list),					   \
			ZB_ZCL_CLUSTER_SERVER_ROLE,				   \
			ZB_ZCL_MANUF_CODE_INVALID				   \
		),								   \
		ZB_ZCL_CLUSTER_DESC(						   \
			ZB_ZCL_CLUSTER_ID_ON_OFF,				   \
			ZB_ZCL_ARRAY_SIZE(on_off_attr_list, zb_zcl_attr_t),	   \
			(on_off_attr_list),					   \
			ZB_ZCL_CLUSTER_SERVER_ROLE,				   \
			ZB_ZCL_MANUF_CODE_INVALID				   \
		),								   \
		ZB_ZCL_CLUSTER_DESC(						   \
			ZB_ZCL_CLUSTER_ID_LEVEL_CONTROL,			   \
			ZB_ZCL_ARRAY_SIZE(level_control_attr_list, zb_zcl_attr_t), \
			(level_control_attr_list),				   \
			ZB_ZCL_CLUSTER_SERVER_ROLE,				   \
			ZB_ZCL_MANUF_CODE_INVALID				   \
		)								   \
	}


/** @cond internals_doc */
/**
 * @brief Declare simple descriptor for Dimmable Light device
 * @param ep_name - endpoint variable name
 * @param ep_id - endpoint ID
 * @param in_clust_num - number of supported input clusters
 * @param out_clust_num - number of supported output clusters
 */
#define ZB_ZCL_DECLARE_HA_DIMMABLE_LIGHT_SIMPLE_DESC(ep_name, ep_id, in_clust_num, out_clust_num) \
	ZB_DECLARE_SIMPLE_DESC(in_clust_num, out_clust_num);					  \
	ZB_AF_SIMPLE_DESC_TYPE(in_clust_num, out_clust_num) simple_desc_##ep_name =		  \
	{											  \
		ep_id,										  \
		ZB_AF_HA_PROFILE_ID,								  \
		ZB_DIMMABLE_LIGHT_DEVICE_ID,							  \
		ZB_DEVICE_VER_DIMMABLE_LIGHT,							  \
		0,										  \
		in_clust_num,									  \
		out_clust_num,									  \
		{										  \
			ZB_ZCL_CLUSTER_ID_BASIC,						  \
			ZB_ZCL_CLUSTER_ID_IDENTIFY,						  \
			ZB_ZCL_CLUSTER_ID_SCENES,						  \
			ZB_ZCL_CLUSTER_ID_GROUPS,						  \
			ZB_ZCL_CLUSTER_ID_ON_OFF,						  \
			ZB_ZCL_CLUSTER_ID_LEVEL_CONTROL,					  \
		}										  \
	}

/** @endcond */ /* internals_doc */

/**
 * @brief Declare endpoint for Dimmable Light device
 * @param ep_name - endpoint variable name
 * @param ep_id - endpoint ID
 * @param cluster_list - endpoint cluster list
 */
#define ZB_DECLARE_DIMMABLE_LIGHT_EP(ep_name, ep_id, cluster_list)		      \
	ZB_ZCL_DECLARE_HA_DIMMABLE_LIGHT_SIMPLE_DESC(ep_name, ep_id,		      \
		ZB_DIMMABLE_LIGHT_IN_CLUSTER_NUM, ZB_DIMMABLE_LIGHT_OUT_CLUSTER_NUM); \
	ZBOSS_DEVICE_DECLARE_REPORTING_CTX(reporting_info## ep_name,		      \
		ZB_DIMMABLE_LIGHT_REPORT_ATTR_COUNT);				      \
	ZBOSS_DEVICE_DECLARE_LEVEL_CONTROL_CTX(cvc_alarm_info## ep_name,	      \
		ZB_DIMMABLE_LIGHT_CVC_ATTR_COUNT);				      \
	ZB_AF_DECLARE_ENDPOINT_DESC(ep_name, ep_id, ZB_AF_HA_PROFILE_ID,	      \
		0,								      \
		NULL,								      \
		ZB_ZCL_ARRAY_SIZE(cluster_list, zb_zcl_cluster_desc_t), cluster_list, \
			(zb_af_simple_desc_1_1_t *)&simple_desc_## ep_name,	      \
			ZB_DIMMABLE_LIGHT_REPORT_ATTR_COUNT,			      \
			reporting_info## ep_name,				      \
			ZB_DIMMABLE_LIGHT_CVC_ATTR_COUNT,			      \
			cvc_alarm_info## ep_name)

/** @} */

#endif /* ZB_DIMMABLE_LIGHT_H */
```

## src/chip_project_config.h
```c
/*
 * Copyright (c) 2026 Nordic Semiconductor ASA
 *
 * SPDX-License-Identifier: LicenseRef-Nordic-5-Clause
 */

/**
 *    @file
 *          Project configuration file for combined Zigbee + Matter application.
 *
 *          This is a place to put application or project-specific overrides
 *          to the default configuration values for general CHIP features.
 *
 */

#pragma once

// Reduce some flash space when the CONFIG_CHIP_MEMORY_PROFILING is selected
#ifdef CONFIG_CHIP_MEMORY_PROFILING
#define CHIP_CONFIG_LOG_MODULE_SecureChannel_PROGRESS 0
#define CHIP_CONFIG_LOG_MODULE_FabricProvisioning_PROGRESS 0
#define CHIP_CONFIG_LOG_MODULE_InteractionModel_PROGRESS 0
#define CHIP_CONFIG_LOG_MODULE_InteractionModel_DETAIL 0
#define CHIP_CONFIG_LOG_MODULE_DataManagement_PROGRESS 0
#endif

// Additional optimizations for combined protocol usage
// Note: CHIP_CONFIG_MAX_FABRICS is now defined via Kconfig (CONFIG_CHIP_MAX_FABRICS)
// and automatically set by the platform's CHIPPlatformConfig.h
#ifndef CHIP_CONFIG_MAX_PEER_NODES
#define CHIP_CONFIG_MAX_PEER_NODES 8
#endif
```

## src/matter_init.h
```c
/*
 * Copyright (c) 2026 Nordic Semiconductor ASA
 *
 * SPDX-License-Identifier: LicenseRef-Nordic-5-Clause
 */

#ifndef MATTER_INIT_H
#define MATTER_INIT_H

#include <stdbool.h>
#include <stdint.h>

#ifdef __cplusplus
extern "C" {
#endif

/**
 * @brief Initialize Matter stack
 * 
 * @return 0 on success, negative errno on failure
 */
int matter_init(void);

/**
 * @brief Update Matter on/off attribute
 * 
 * @param on true for on, false for off
 */
void matter_update_onoff(bool on);

/**
 * @brief Update Matter level control attribute
 * 
 * @param level Level value (0-255)
 */
void matter_update_level(uint8_t level);

#ifdef __cplusplus
}
#endif

#endif /* MATTER_INIT_H */
```

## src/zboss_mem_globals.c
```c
/*
 * Copyright (c) 2026 Nordic Semiconductor ASA
 *
 * SPDX-License-Identifier: LicenseRef-Nordic-5-Clause
 */

/**
 * @file zboss_mem_globals.c
 *
 * Holds ZBOSS configurable RAM globals (via zb_mem_config_context.h) in a
 * dedicated translation unit. When linking LTO-built prebuilt libzboss with
 * CONFIG_LTO, zb_memconfig.c in the archive is built with -fno-lto (weak
 * defaults); defining the strong gc_* arrays in another LTO-compiled file
 * triggers ld "size of symbol ... changed" warnings. Compiling this file
 * with -fno-lto keeps weak + strong resolution in the classic ELF path.
 */

#include <zboss_api.h>
#include <zb_mem_config_med.h>
```

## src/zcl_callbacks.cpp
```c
/*
 * Copyright (c) 2026 Nordic Semiconductor ASA
 *
 * SPDX-License-Identifier: LicenseRef-Nordic-5-Clause
 */

#include <lib/support/logging/CHIPLogging.h>

#include "app_task_matter.h"

#include <app-common/zap-generated/attributes/Accessors.h>
#include <app-common/zap-generated/ids/Attributes.h>
#include <app-common/zap-generated/ids/Clusters.h>
#include <app/ConcreteAttributePath.h>

using namespace ::chip;
using namespace ::chip::app::Clusters;
using namespace ::chip::app::Clusters::OnOff;

void MatterPostAttributeChangeCallback(const chip::app::ConcreteAttributePath &attributePath, uint8_t type,
				       uint16_t size, uint8_t *value)
{
	(void)type;
	(void)size;

	ClusterId clusterId = attributePath.mClusterId;
	AttributeId attributeId = attributePath.mAttributeId;

	if (clusterId == OnOff::Id && attributeId == OnOff::Attributes::OnOff::Id) {
		ChipLogProgress(Zcl, "Cluster OnOff: attribute OnOff set to %" PRIu8 "", *value);

#if defined(CONFIG_PWM)
		AppTask::Instance().GetPWMDevice().InitiateAction(*value ? Nrf::PWMDevice::ON_ACTION :
									   Nrf::PWMDevice::OFF_ACTION,
								  static_cast<int32_t>(LightingActor::Remote), value);
#else
		Nrf::GetBoard().GetLED(Nrf::DeviceLeds::LED2).Set(*value);
#endif

	} else if (clusterId == LevelControl::Id && attributeId == LevelControl::Attributes::CurrentLevel::Id) {
		ChipLogProgress(Zcl, "Cluster LevelControl: attribute CurrentLevel set to %" PRIu8 "", *value);
#if defined(CONFIG_PWM)
		if (AppTask::Instance().GetPWMDevice().IsTurnedOn()) {
			AppTask::Instance().GetPWMDevice().InitiateAction(
				Nrf::PWMDevice::LEVEL_ACTION, static_cast<int32_t>(LightingActor::Remote), value);
		} else {
			ChipLogDetail(Zcl, "LED is off. Try to use move-to-level-with-on-off instead of move-to-level");
		}
#endif
	}
}

/** @brief OnOff Cluster Init
 *
 * This function is called when a specific cluster is initialized. It gives the
 * application an opportunity to take care of cluster initialization procedures.
 * It is called exactly once for each endpoint where cluster is present.
 *
 * @param endpoint   Ver.: always
 *
 * TODO Issue #3841
 * emberAfOnOffClusterInitCallback happens before the stack initialize the cluster
 * attributes to the default value.
 * The logic here expects something similar to the deprecated Plugins callback
 * emberAfPluginOnOffClusterServerPostInitCallback.
 *
 */
void emberAfOnOffClusterInitCallback(EndpointId endpoint)
{
	Protocols::InteractionModel::Status status;
	bool storedValue;

	ChipLogDetail(Zcl, "OnOff Cluster initialization callback for endpoint %" PRIu16, endpoint);

	/* Read storedValue on/off value */
	status = Attributes::OnOff::Get(endpoint, &storedValue);

	if (status == Protocols::InteractionModel::Status::Success) {
		/* Set actual state to the cluster state that was last persisted */
#if defined(CONFIG_PWM)
		AppTask::Instance().InitPWMDDevice();

		AppTask::Instance().GetPWMDevice().InitiateAction(
			storedValue ? Nrf::PWMDevice::ON_ACTION : Nrf::PWMDevice::OFF_ACTION,
			static_cast<int32_t>(LightingActor::Remote), nullptr);
#else
		Nrf::GetBoard().GetLED(Nrf::DeviceLeds::LED2).Set(storedValue);
#endif
	} else {
		ChipLogError(Zcl, "Failed to read stored OnOff value: 0x%x", to_underlying(status));
	}

	ChipLogDetail(Zcl, "Updating cluster state after OnOff Cluster Init");
	AppTask::Instance().UpdateClusterState();
}
```
